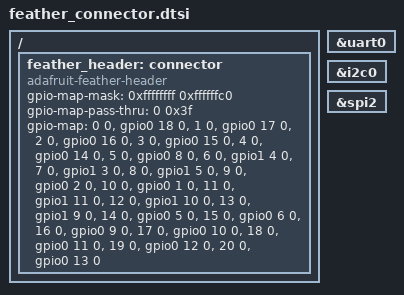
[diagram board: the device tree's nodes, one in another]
/*
 * SPDX-FileCopyrightText: Copyright 2025 Sam Blenny
 * SPDX-License-Identifier: Apache-2.0
 *
 * For CircuitPython pin assignments, see:
 *   https://github.com/adafruit/circuitpython/blob/main/ports/espressif/boards/adafruit_feather_esp32s3_tft/pins.c
 * For an explanation of when to use Zephyr's esp32 gpio0 vs gpio1, see:
 *   https://www.zephyrproject.org/how-to-set-up-esp32-gpio-pins-in-zephyr-rtos/
 */

/ {
	feather_header: connector {
		compatible = "adafruit-feather-header";
		#gpio-cells = <2>;
		gpio-map-mask = <0xffffffff 0xffffffc0>;
		gpio-map-pass-thru = <0 0x3f>;
		gpio-map =
			< 0 0 &gpio0 18 0>,  /* A0 */
			< 1 0 &gpio0 17 0>,  /* A1 */
			< 2 0 &gpio0 16 0>,  /* A2 */
			< 3 0 &gpio0 15 0>,  /* A3 */
			< 4 0 &gpio0 14 0>,  /* A4 */
			< 5 0 &gpio0  8 0>,  /* A5 */
			< 6 0 &gpio1  4 0>,  /* SCK:  GPIO36 -> &gpio1 4 */
			< 7 0 &gpio1  3 0>,  /* MOSI: GPIO35 -> &gpio1 3 */
			< 8 0 &gpio1  5 0>,  /* MISO: GPIO37 -> &gpio1 5 */
			< 9 0 &gpio0  2 0>,  /* RX */
			<10 0 &gpio0  1 0>,  /* TX */
			/* DBG pin is marked as TXD0 on the schematic. As far as I can
			*  tell, that probably means U0TXD/GPIO43 from the ESP32-S3-MINI-1
			*  datasheet and ESP32-S3 technical reference manual.
			*  CAUTION: this might be wrong.
			*/
			<11 0 &gpio1 11 0>,  /* DBG: GPIO43 -> &gpio1 11 */

			<12 0 &gpio1 10 0>,  /* SDA: GPIO42 -> &gpio1 10 */
			<13 0 &gpio1  9 0>,  /* SCL: GPIO41 -> &gpio1  9 */
			<14 0 &gpio0  5 0>,  /* D5 */
			<15 0 &gpio0  6 0>,  /* D6 */
			<16 0 &gpio0  9 0>,  /* D9 */
			<17 0 &gpio0 10 0>,  /* D10 */
			<18 0 &gpio0 11 0>,  /* D11 */
			<19 0 &gpio0 12 0>,  /* D12 */
			<20 0 &gpio0 13 0>;  /* D13 */
	};
};

feather_serial: &uart0 {};
feather_i2c: &i2c0 {};
feather_spi: &spi2 {};
